# moonlight_application register map
Vendor: Nordic Semiconductor; Series: lumos; File version: 1
CPU: CM33 r0p4, little endian, MPU, FPU, 3 interrupt priority bits, 176 interrupts, 4 SAU regions
Registers are 32-bit, read-write, reset 0x0 unless marked. A register's access mark holds for its fields unless they carry their own. Offsets are from the block's base; [hi:lo] are bit positions; lines under a group give offsets from that group; {n}, {i} and the like mark numbered series; 'fields as' and 'values as' point back to an identical list.

## GLOBAL_CRACEN_NS — CRACEN 0
Base 0x50048000
Same registers: GLOBAL_CRACEN_S 0x50048000 (alternate view of GLOBAL_CRACEN_NS)
0x100 EVENTS_CRYPTOMASTER — Event indicating that interrupt triggered at Cryptomaster
  [0] EVENTS_CRYPTOMASTER
    0=NotGenerated (Event not generated); 1=Generated (Event generated)
0x104 EVENTS_RNG — Event indicating that interrupt triggered at RNG
  [0] EVENTS_RNG
    values as EVENTS_CRYPTOMASTER.EVENTS_CRYPTOMASTER
0x108 EVENTS_PKEIKG — Event indicating that interrupt triggered at PKE or IKG
  [0] EVENTS_PKEIKG
    values as EVENTS_CRYPTOMASTER.EVENTS_CRYPTOMASTER
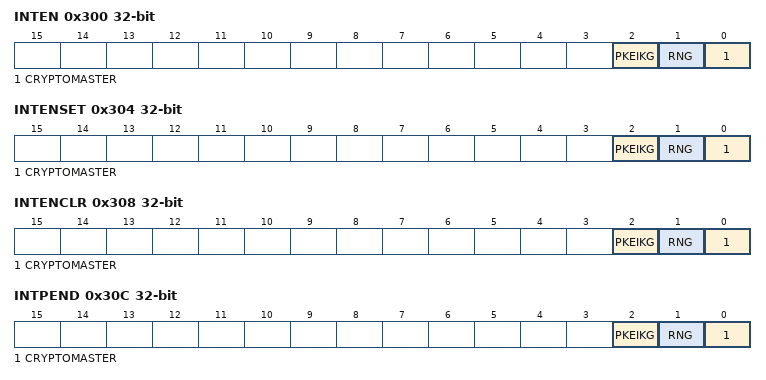
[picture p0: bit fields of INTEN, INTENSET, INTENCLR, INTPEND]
0x300 INTEN — Enable or disable interrupt
  [all] fields
    0=Disabled; 1=Enabled
  [2] PKEIKG — Enable or disable interrupt for event PKEIKG
  [1] RNG — Enable or disable interrupt for event RNG
  [0] CRYPTOMASTER — Enable or disable interrupt for event CRYPTOMASTER
0x304 INTENSET — Enable interrupt
  [all] fields
    on read: 0=Disabled (Read: Disabled); 1=Enabled (Read: Enabled) | on write: 1=Set (Enable)
  [2] PKEIKG — Write '1' to enable interrupt for event PKEIKG
  [1] RNG — Write '1' to enable interrupt for event RNG
  [0] CRYPTOMASTER — Write '1' to enable interrupt for event CRYPTOMASTER
0x308 INTENCLR — Disable interrupt
  [all] fields
    on read: 0=Disabled (Read: Disabled); 1=Enabled (Read: Enabled) | on write: 1=Clear (Disable)
  [2] PKEIKG — Write '1' to disable interrupt for event PKEIKG
  [1] RNG — Write '1' to disable interrupt for event RNG
  [0] CRYPTOMASTER — Write '1' to disable interrupt for event CRYPTOMASTER
0x30C INTPEND ro — Pending interrupts
  [all] fields
    on read: 0=NotPending (Read: Not pending); 1=Pending (Read: Pending)
  [2] PKEIKG — Read pending status of interrupt for event PKEIKG
  [1] RNG — Read pending status of interrupt for event RNG
  [0] CRYPTOMASTER — Read pending status of interrupt for event CRYPTOMASTER
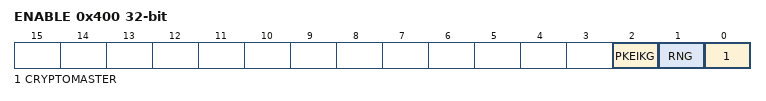
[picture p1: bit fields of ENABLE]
0x400 ENABLE — Enable CRACEN peripheral modules.
  [2] PKEIKG — Enable PKE and IKG
    0=Disabled (PKE and IKG disabled.); 1=Enabled (PKE and IKG enabled.)
  [1] RNG — Enable RNG
    0=Disabled (RNG disabled.); 1=Enabled (RNG enabled.)
  [0] CRYPTOMASTER — Enable cryptomaster
    0=Disabled (Cryptomaster disabled.); 1=Enabled (Cryptomaster enabled.)
0x404 PROTECTEDRAMLOCK — Lock the access to the protected RAM.
  [0] ENABLE — Enable the lock
    0=Disabled (Lock disabled.); 1=Enabled (Lock enabled.)
0x404 SEEDRAMLOCK (alternate view of PROTECTEDRAMLOCK) — Lock the access to the RAM used for the seed.
  fields as PROTECTEDRAMLOCK
{0x408+4i} SEED[{i}] (i=0..11) wo — Description collection: Seed word [n] for symmetric and asymmetric key generation.
  [31:0] VAL — Seed value

## GLOBAL_SPI00_NS — Serial Peripheral Interface 0
Base 0x4004A000
Same registers: GLOBAL_SPI20_NS 0x400C6000, GLOBAL_SPI21_NS 0x400C7000, GLOBAL_SPI22_NS 0x400C8000, GLOBAL_SPI30_NS 0x40104000, GLOBAL_SPI00_S 0x5004A000, GLOBAL_SPI20_S 0x500C6000, GLOBAL_SPI21_S 0x500C7000, GLOBAL_SPI22_S 0x500C8000, GLOBAL_SPI30_S 0x50104000
0x108 EVENTS_READY — TXD byte sent and RXD byte received
  [0] EVENTS_READY
    0=NotGenerated (Event not generated); 1=Generated (Event generated)
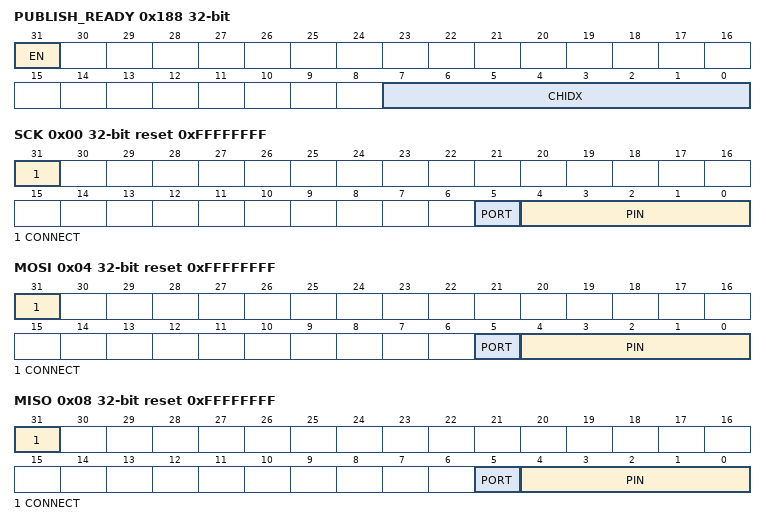
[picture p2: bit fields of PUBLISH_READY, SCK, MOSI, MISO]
0x188 PUBLISH_READY — Publish configuration for event READY
  [31] EN
    0=Disabled (Disable publishing); 1=Enabled (Enable publishing)
  [7:0] CHIDX — DPPI channel that event READY will publish to
0x300 INTEN — Enable or disable interrupt
  [2] READY — Enable or disable interrupt for event READY
    0=Disabled; 1=Enabled
0x304 INTENSET — Enable interrupt
  [2] READY — Write '1' to enable interrupt for event READY
    on read: 0=Disabled (Read: Disabled); 1=Enabled (Read: Enabled) | on write: 1=Set (Enable)
0x308 INTENCLR — Disable interrupt
  [2] READY — Write '1' to disable interrupt for event READY
    on read: 0=Disabled (Read: Disabled); 1=Enabled (Read: Enabled) | on write: 1=Clear (Disable)
0x500 ENABLE — Enable SPI
  [3:0] ENABLE — Enable or disable SPI
    0=Disabled (Disable SPI); 1=Enabled (Enable SPI)
0x508 PSEL group — Unspecified
  0x00 SCK reset 0xFFFFFFFF — Pin select for SCK
    [31] CONNECT — Connection
      1=Disconnected; 0=Connected
    [5] PORT — Port number
    [4:0] PIN — Pin number
  0x04 MOSI reset 0xFFFFFFFF — Pin select for MOSI signal
    fields as PSEL.SCK
  0x08 MISO reset 0xFFFFFFFF — Pin select for MISO signal
    fields as PSEL.SCK
0x518 RXD ro
  [7:0] RXD — RX data received. Double buffered
0x51C TXD
  [7:0] TXD — TX data to send. Double buffered.
0x52C PRESCALER reset 0x40 — The prescaler is used to set the SPI frequency.
  [6:0] DIVISOR — Core clock to SCK divisor
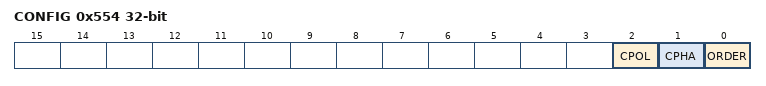
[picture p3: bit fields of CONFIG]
0x554 CONFIG — Configuration register
  [2] CPOL — Serial clock (SCK) polarity
    0=ActiveHigh; 1=ActiveLow
  [1] CPHA — Serial clock (SCK) phase
    0=Leading (Sample on leading edge of clock, shift serial data on trailing edge); 1=Trailing (Sample on trailing edge of clock, shift serial data on leading edge)
  [0] ORDER — Bit order
    0=MsbFirst (Most significant bit shifted out first); 1=LsbFirst (Least significant bit shifted out first)
